# UART3 register map
Vendor: Texas Instruments
Peripheral module from a debugger description file (folder omap36xx).
Registers are 32-bit, access per field, reset 0x0 unless marked. A register's access mark holds for its fields unless they carry their own. Offsets are as the file gives them; lines under a group give offsets from that group; [hi:lo] are bit positions; {n}, {i} and the like mark numbered series; 'fields as' and 'values as' point back to an identical list; <NAME> marks a mode.

## UART3
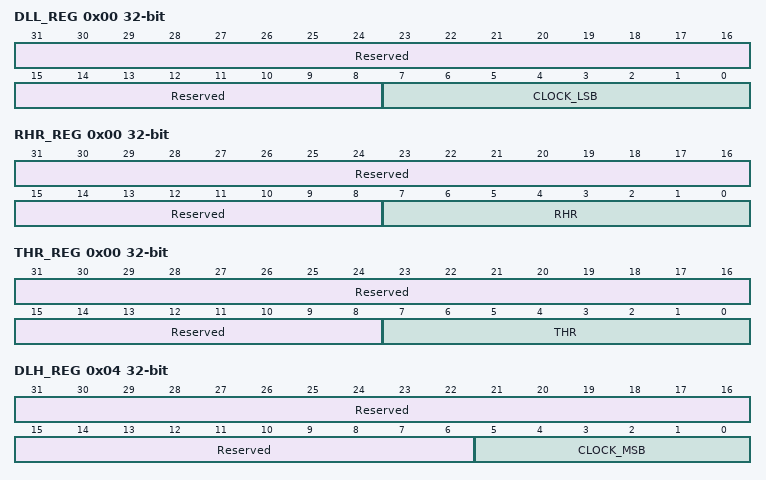
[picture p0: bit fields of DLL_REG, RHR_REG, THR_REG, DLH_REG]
0x00 DLL_REG — Divisor latches low
  [31:8] Reserved ro — Read returns 0.
  [7:0] CLOCK_LSB rw — Stores the 8-bit LSB divisor value
0x00 RHR_REG ro (reset mask 0xFFFFFF00) — Receive holding register
  [31:8] Reserved — Read returns 0.
  [7:0] RHR — Receive holding register
0x00 THR_REG wo (reset mask 0xFFFFFF00) — Transmit holding register
  [31:8] Reserved — Write has no functional effect.
  [7:0] THR — Transmit holding register
0x04 DLH_REG — Divisor latches high
  [31:6] Reserved ro — Read returns 0.
  [5:0] CLOCK_MSB rw — Stores the 6-bit most-significant bit (MSB) divisor value
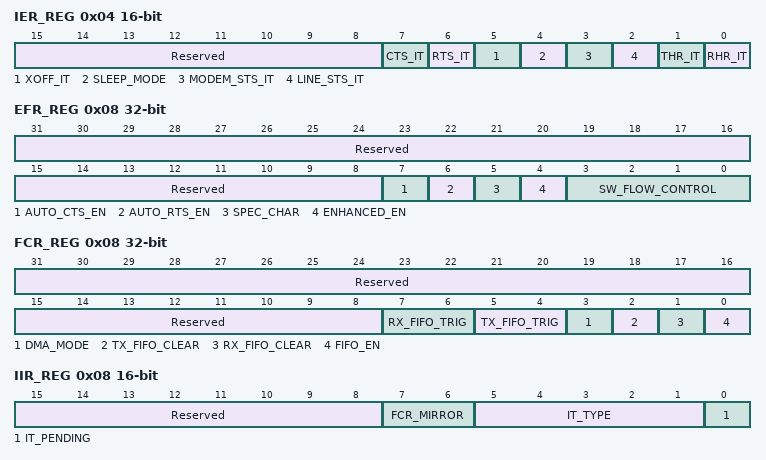
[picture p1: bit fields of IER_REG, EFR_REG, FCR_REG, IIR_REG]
0x04 IER_REG 16-bit rw — Interrupt enable register
  [15:8] Reserved — Read returns 0x00. Write has no functional effect.
  [7] CTS_IT — Can be written only whenEFR_REG[4] = 1
    0=Disables the nCTS interrupt; 1=Enables the nCTS interrupt
  [6] RTS_IT — Can be written only whenEFR_REG[4] = 1
    0=Disables the interrupt; 1=Enables the nRTS interrupt
  [5] XOFF_IT — Can be written only whenEFR_REG[4] = 1
    0=Disables the XOFF interrupt; 1=Enables the XOFF interrupt
  [4] SLEEP_MODE — Can be only written whenEFR_REG[4] = 1
    0=Disables sleep mode; 1=Enables sleep mode (stop baud rate clock when the module is inactive)
  [3] MODEM_STS_IT
    0=Disables the modem status register interrupt; 1=Enables the modem status register interrupt
  [2] LINE_STS_IT
    0=Disables the receiver line status interrupt; 1=Enables the receiver line status interrupt
  [1] THR_IT
    0=Disables the THR interrupt; 1=Enables the THR interrupt
  [0] RHR_IT
    0=Disables the RHR interrupt and time out interrupt; 1=Enables the RHR interrupt and time out interrupt
0x08 EFR_REG — Enhanced feature register
  [31:8] Reserved ro — Read returns 0.
  [7] AUTO_CTS_EN rw — Auto-CTS enable bit (UART mode only)
    0=Normal operation; 1=Auto-CTS flow control is enabled; transmission is halted when the nCTS pin is high (inactive)
  [6] AUTO_RTS_EN rw — Auto-RTS enable bit (UART mode only)
    0=Normal operation; 1=Auto-RTS flow control is enabled; nRTS pin goes high (inactive) when the receiver FIFO HALT trigger level,[3:0], is reached and goes low (active) when the receiver FIFO RESTORE transmission trigger level is reached
  [5] SPEC_CHAR rw — (UART mode only) Special character detect
    0=Normal operation; 1=Special character detect enable. Received data is compared with XOFF2 data. If a match occurs, the received data is transferred to RX FIFO and bit 4 is set to 1 to indicate that a special character was detected.
  [4] ENHANCED_EN rw — Enhanced functions write enable bit
    0=Disables writing to bits [7:4], bits [5:4], and bits [7:5]; 1=Enables writing to bits [7:4], bits [5:4], and bits [7:5]
  [3:0] SW_FLOW_CONTROL rw — Combinations of software flow control can be selected by programming bit [3:0].See. In IrDA mode, bits [1:0] select IR address to check. See , IR Address Checking. .
0x08 FCR_REG wo — FIFO control register
  [31:8] Reserved — Write has no functional effect.
  [7:6] RX_FIFO_TRIG — Sets the trigger level for the RX FIFO: IfSCR_REG[7] = 0 and TLR_REG[7:4]≠ 0000, RX_FIFO_TRIG is not considered.If[7] = 1, RX_FIFO_TRIG is 2 LSB of the trigger level (1 to 63 on 6 bits) with a granularity of 1. . If[7] = 0 and [7:4] = 0000: .
    0=8 characters; 1=16 characters; 2=56 characters; 3=60 characters
  [5:4] TX_FIFO_TRIG — Can be written only ifEFR_REG[4] = 1. Sets the trigger level for the TX FIFO. If SCR_REG[6] = 0 and TLR_REG[3:0] ≠ 0000, TX_FIFO_TRIG is not considered.If[6] = 1, RX_FIFO_TRIG is 2 LSB of the trigger level (1 to 63 on 6 bits) with a granularity of 1. . If[6] = 0 and [3:0] = 0000: .
    0=8 characters; 1=16 characters; 2=32 characters; 3=56 characters
  [3] DMA_MODE — Can be changed only when the baud clock is not running (DLL_REG and DLH_REG set to 0).This register is considered if[0] = 0. .
    0=DMA_MODE 0 (No DMA); 1=DMA_MODE 1 (UART_NDMA_REQ[0] in TX, UART_NDMA_REQ[1] in RX)
  [2] TX_FIFO_CLEAR — Clears the TX FIFO
    0=No change; 1=Clears the transmit FIFO and resets its counter logic to 0. Returns to 0 after clearing FIFO.
  [1] RX_FIFO_CLEAR — Clears the RX FIFO.
    0=No change; 1=Clears the receive FIFO and resets its counter logic to 0. Returns to 0 after clearing FIFO.
  [0] FIFO_EN — Can be changed only when the baud clock is not running (DLL_REG and DLH_REG set to 0).
    0=Disables the transmit and receive FIFOs. The transmit and receive holding registers are 1-byte FIFOs.; 1=Enables the transmit and receive FIFOs. The transmit and receive holding registers are 64-byte FIFOs.
0x08 IIR_REG 16-bit access not given (reset mask 0xFFFE) — Interrupt Identification register
  [15:8] Reserved ro — Read returns 0x00.
  [7:6] FCR_MIRROR ro — Mirror the contents ofFCR_REG[0] on both bits.
  [5:1] IT_TYPE ro — Seven possible interrupts in UART mode; other combinations never occur:
    0=Modem interrupt. Priority = 4; 1=THR interrupt. Priority = 3; 2=RHR interrupt. Priority = 2; 3=Receiver line status error. Priority = 1; 6=Rx timeout. Priority = 2; 8=Xoff/special character. Priority = 5; 16=CTS, RTS change state from active (low) to inactive (high). Priority = 6
  [0] IT_PENDING — 0x0: (access An interrupt is pending.)
    1=No interrupt is pending
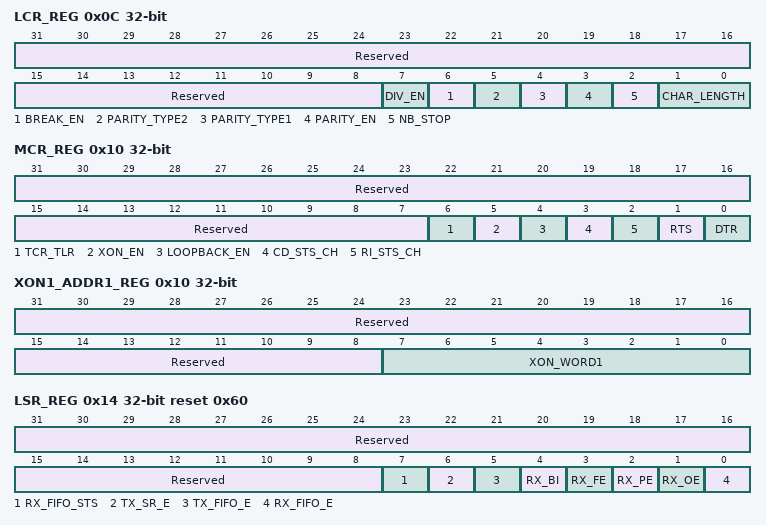
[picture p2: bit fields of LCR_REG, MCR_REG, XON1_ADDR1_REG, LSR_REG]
0x0C LCR_REG — Line control register
  [31:8] Reserved ro — Read returns 0
  [7] DIV_EN rw
    0=Operational mode; 1=Divisor latch enable; put the module in Configuration_Mode_A/B. Allows access to, , and other registers (see , UART/IrDA/CIR Register Mapping Summary). Configuration_Mode_B: [7:0] = 0xBF Else, Configuration_Mode_A
  [6] BREAK_EN rw — Break control bit. UART mode only.Note:When [6] is set to 1, the TX line is forced to 0 and remains in this state as long as [6] = 1. .
    0=Normal operating condition; 1=Forces the transmitter output to go low to alert the communication terminal. TX line is forced to 0 and remains in this state while BREAK_EN = 1.
  [5] PARITY_TYPE2 rw — Selects the forced parity format (ifLCR_REG[3] = 1). UART mode only. If LCR_REG[5] = 1and LCR_REG[4] = 0, the parity bit is forced to 1 in the transmitted and received data. If LCR_REG[5] = 1 and LCR_REG[4] = 1, the parity bit is forced to 0 in the transmitted and received data.
  [4] PARITY_TYPE1 rw — UART mode only
    0=Odd parity is generated (if[3] = 1); 1=Even parity is generated (if[3] = 1)
  [3] PARITY_EN rw — UART mode only
    0=No parity; 1=A parity bit is generated during transmission, and the receiver checks for received parity
  [2] NB_STOP rw — Specifies the number of stop bits. UART mode only.
    0=1 stop bit (word length = 5, 6, 7, 8); 1=1.5 stop bits (word length = 5)1 - 2 stop bits (word length = 6, 7, 8)
  [1:0] CHAR_LENGTH rw — Specifies the word length to be transmitted or received. UART mode only.
    {v}={v+5} bits (v=0..3)
0x10 MCR_REG access not given (reset mask 0xFFFFFFFE) — Modem control register
  [31:7] Reserved ro — Read returns 0.
  [6] TCR_TLR rw — Can be written only whenEFR_REG[4] ENHANCED_EN = 1
    0=No action; 1=Enables access to the and registers
  [5] XON_EN rw — Can be written only whenEFR_REG[4] ENHANCED_EN = 1
    0=Disable XON any function; 1=Enable XON any function
  [4] LOOPBACK_EN rw — In this mode, the[3:0] signals are looped back into [7:4]. The transmit output is looped back to the receive input internally. .
    0=Normal operating mode; 1=Enable local loopback mode (internal)
  [3] CD_STS_CH rw
    0=In loopback, forces nDCD input high and IRQ outputs to INACTIVE state; 1=In loopback, forces nDCD input low and IRQ outputs to INACTIVE state
  [2] RI_STS_CH rw
    0=In loopback, forces nRI input inactive (high); 1=In loopback, forces nRI input active (low)
  [1] RTS rw — In loop back, controlsMSR_REG[4].If auto-RTS is enabled, the nRTS output is controlled by hardware flow control.
    0=Force nRTS output to inactive (high); 1=Force nRTS output to active (low)
  [0] DTR — 0: (access Force DTR output (used in loop back mode) to inactive (high))
    1=Force DTR output (used in loop back mode) to active (low)
0x10 XON1_ADDR1_REG — UART mode: XON1 character, IrDA mode: ADDR1 address
  [31:8] Reserved ro — Read returns 0
  [7:0] XON_WORD1 rw — Used to store the 8-bit XON1 character in UART modes and ADDR1 address 1 for IrDA modes
0x14 LSR_REG ro reset 0x60 — Line status register
  [31:8] Reserved — Read returns 0.
  [7] RX_FIFO_STS
    0=Normal operation; 1=At least one parity error, framing error, or break indication in the RX FIFO. Bit 7 is cleared when no errors are present in the RX FIFO.
  [6] TX_SR_E
    0=Transmitter hold (TX FIFO) and shift registers are not empty; 1=Transmitter hold (TX FIFO) and shift registers are empty
  [5] TX_FIFO_E
    0=Transmit hold register (TX FIFO) is not empty; 1=Transmit hold register (TX FIFO) is empty. The transmission is not necessarily complete.
  [4] RX_BI
    0=No break condition; 1=A break was detected while the data being read from the RX FIFO was being received (RX input was low for one character + 1 bit time frame)
  [3] RX_FE
    0=No framing error in data being read from RX FIFO; 1=Framing error occurred in data being read from RX FIFO (received data did not have a valid stop bit)
  [2] RX_PE
    0=No parity error in data being read from RX FIFO; 1=Parity error in data being read from RX FIFO
  [1] RX_OE
    0=No overrun error; 1=Overrun error occurred. Set when the character held in the receive shift register is not transferred to the RX FIFO. This case occurs only when receive FIFO is full.
  [0] RX_FIFO_E
    0=No data in the receive FIFO; 1=At least one data character in the RX FIFO
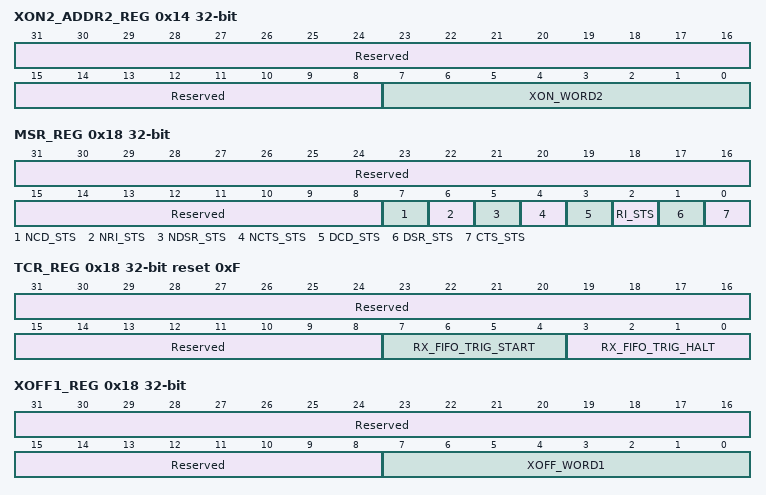
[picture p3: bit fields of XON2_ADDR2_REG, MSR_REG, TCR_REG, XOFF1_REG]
0x14 XON2_ADDR2_REG
  [31:8] Reserved ro — Read returns 0.
  [7:0] XON_WORD2 rw — Stores the 8-bit XON2 character in UART modes and ADDR2 address 2 for IrDA modes
0x18 MSR_REG ro (reset mask 0xFFFFFF0F) — Modem status register. UART mode only.
  [31:8] Reserved — Read returns 0x00.
  [7] NCD_STS — In loopback mode, it is equivalent toMCR_REG[3].
  [6] NRI_STS — This bit is the complement of the nRI input. In loopback mode, it is equivalent toMCR_REG[2].
  [5] NDSR_STS — In loopback mode, it is equivalent toMCR_REG[0].
  [4] NCTS_STS — This bit is the complement of the nCTS input. In loopback mode, it is equivalent toMCR_REG[1].
  [3] DCD_STS — Indicates thatMCR_REG[3] in loopback changed. Cleared on a read.
  [2] RI_STS — Indicates that nRI input (orMCR_REG[2] in loopback) changed state from low to high. Cleared on a read.
  [1] DSR_STS
    1=Indicates that[0] in loopback changed state. Cleared on a read.
  [0] CTS_STS
    1=Indicates that nCTS input (or[1] in loopback) changed state. Cleared on a read.
0x18 TCR_REG reset 0xF — Transmission control register.
  [31:8] Reserved ro — Read returns 0.
  [7:4] RX_FIFO_TRIG_START rw — RX FIFO trigger level to RESTORE transmission (0 to 60)
  [3:0] RX_FIFO_TRIG_HALT rw — RX FIFO trigger level to HALT transmission (0 to 60)
0x18 XOFF1_REG — UART mode XOFF1 character
  [31:8] Reserved ro — Read returns 0
  [7:0] XOFF_WORD1 rw — Stores the 8-bit XOFF1 character used in UART modes
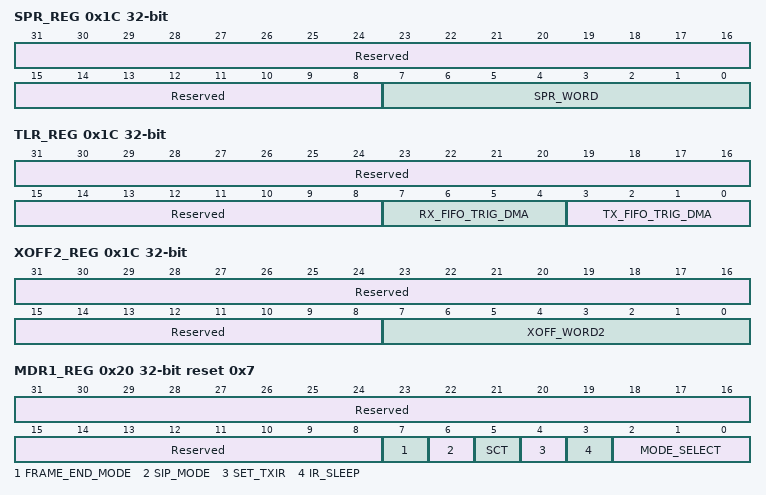
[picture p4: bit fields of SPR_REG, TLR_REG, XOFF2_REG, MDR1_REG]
0x1C SPR_REG — Scratchpad register
  [31:8] Reserved ro — Read returns 0x00.
  [7:0] SPR_WORD rw — Scratchpad register
0x1C TLR_REG — Trigger level register.
  [31:8] Reserved ro — Read returns 0x00.
  [7:4] RX_FIFO_TRIG_DMA rw — Receive FIFO trigger level
  [3:0] TX_FIFO_TRIG_DMA rw — Transmit FIFO trigger level
0x1C XOFF2_REG — UART mode XOFF2 character.
  [31:8] Reserved ro — Read returns 0.
  [7:0] XOFF_WORD2 rw — Stores the 8-bit XOFF2 character used in UART modes
0x20 MDR1_REG reset 0x7 — Mode definition register 1.
  [31:8] Reserved ro — Read returns 0.
  [7] FRAME_END_MODE rw — IrDA mode only
    0=Frame-length method; 1=Set EOT bit method
  [6] SIP_MODE rw — MIR/FIR modes only. IrDA only.
    0=Manual SIP mode: SIP is generated with the control of[3]; 1=Automatic SIP mode: SIP is generated after each transmission
  [5] SCT rw — Store and control the transmission.Note:Before starting any transmission, there must be no reception ongoing. .
    0=Starts the infrared transmission when a value is written to; 1=Starts the infrared transmission with the control of[2]
  [4] SET_TXIR rw — Used to configure the infrared transceiver. IrDA only.
    0=a) No action if MDR2[7]=0b) TXIR pin output is forced low if MDR2[7]=1; 1=TXIR pin output is forced high (not dependant on value of MDR2[7])
  [3] IR_SLEEP rw
    0=IrDA/CIR sleep mode disabled; 1=IrDA/CIR sleep mode enabled
  [2:0] MODE_SELECT rw — UART-IrDA-CIR mode selection
    0=UART 16x mode; 1=SIR mode; 2=UART 16x auto-baud; 3=UART 13x mode; 4=MIR mode; 5=FIR mode; 6=CIR mode; 7=Disable (default state)
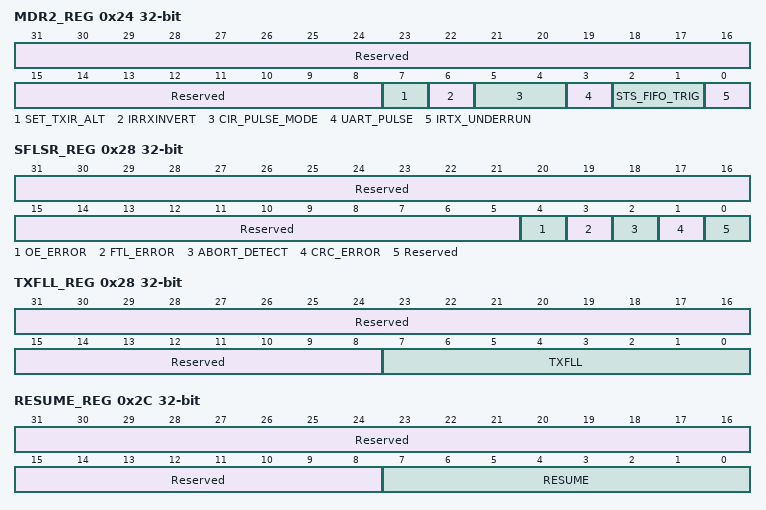
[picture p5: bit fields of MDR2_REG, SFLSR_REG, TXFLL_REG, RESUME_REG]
0x24 MDR2_REG — Mode definition register 2
  [31:8] Reserved ro — Read returns 0x00.
  [7] SET_TXIR_ALT rw — Provide alternate functionnality for MDR1[4] (SET_TXIR)
    0=Normal mode; 1=Alternate mode for SET_TXIR
  [6] IRRXINVERT rw — Only for IR mode (IrDA and CIR). Invert RX pin in the module before the voting or sampling system logic of the infrared block. This does not affect the RX path in UART modem modes.
    0=Inversion is performed; 1=No inversion is performed
  [5:4] CIR_PULSE_MODE rw — CIR pulse modulation definition. Defines high level of the pulse width associated with a digit:
    {v}=Pulse width of {v+3} from 12 cycles (v=0..3)
  [3] UART_PULSE rw — UART mode only. Used to allow pulse shaping in UART mode.
    0=Normal UART mode; 1=UART mode with pulse shaping
  [2:1] STS_FIFO_TRIG rw — Only for IR-IrDA modeFrame status FIFO threshold select: .
    0=1 entry; 1=4 entries; 2=7 entries; 3=8 entries
  [0] IRTX_UNDERRUN ro — IrDA transmission status interrupt. When theIIR_REG[5] interrupt occurs, the meaning of the interrupt is:
    0=The last bit of the frame was transmitted successfully without error; 1=An underrun occurred. The last bit of the frame was transmitted but with an underrun error. The bit is reset to 0 when the register is read.
0x28 SFLSR_REG ro (reset mask 0xFFFFFFE1) — Status FIFO line status register
  [31:5] Reserved — Read returns 0.
  [4] OE_ERROR
    1=Overrun error in RX FIFO when frame at top of RX FIFO was received. Top of RX FIFO = next frame to be read from RX FIFO.
  [3] FTL_ERROR — Frame-too-long error
    1=Frame-length too long error in frame at top of RX FIFO
  [2] ABORT_DETECT
    1=Abort pattern detected in frame at top of RX FIFO; 1=CRC error in frame at top of RX FIFO
  [1] CRC_ERROR
  [0] Reserved — Read returns 0.
0x28 TXFLL_REG wo — Transmit frame length register low
  [31:8] Reserved — Write has no functional effect.
  [7:0] TXFLL — LSB register used to specify the frame length
0x2C RESUME_REG ro — IR-IrDA and IR-CIR modes only
  [31:8] Reserved — Read returns 0x00
  [7:0] RESUME — Dummy read to restart the TX or RX
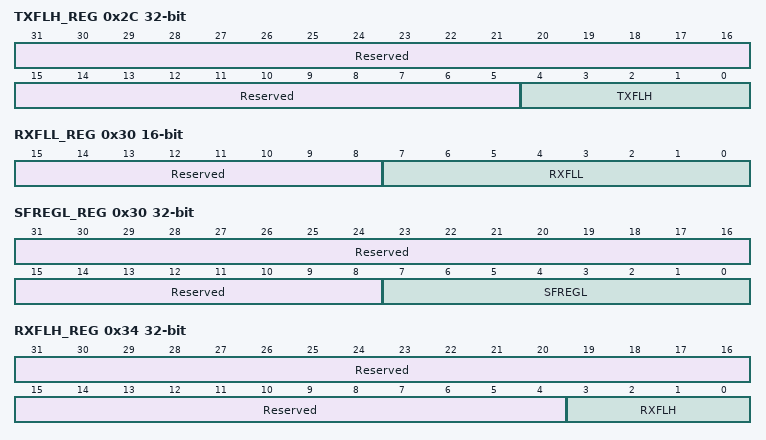
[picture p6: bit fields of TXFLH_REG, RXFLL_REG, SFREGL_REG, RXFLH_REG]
0x2C TXFLH_REG — Transmit frame length register low
  [31:5] Reserved ro — Read returns 0.
  [4:0] TXFLH wo — MSB register used to specify the frame length
0x30 RXFLL_REG 16-bit wo — Received frame length register low
  [15:8] Reserved — Write has no functional effect.
  [7:0] RXFLL — LSB register used to specify the frame length in reception
0x30 SFREGL_REG ro (reset mask 0xFFFFFF00) — Status FIFO register low
  [31:8] Reserved — Read returns 0x00.
  [7:0] SFREGL — LSB part of the frame length
0x34 RXFLH_REG wo — Received frame length register high
  [31:4] Reserved — Write has no functional effect.
  [3:0] RXFLH — MSB register used to specify the frame length in reception
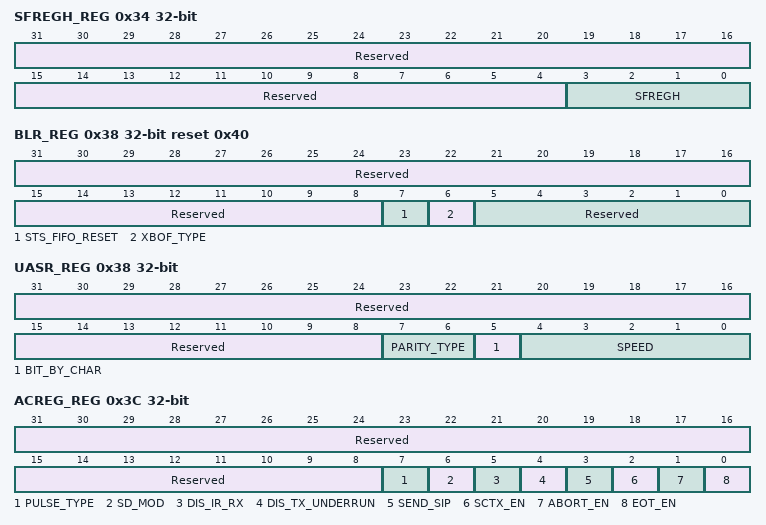
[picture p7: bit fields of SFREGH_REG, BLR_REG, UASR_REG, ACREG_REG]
0x34 SFREGH_REG ro (reset mask 0xFFFFFFF0) — Status FIFO register high
  [31:4] Reserved — Read returns 0.
  [3:0] SFREGH — MSB part of the frame length
0x38 BLR_REG reset 0x40 — BOF control register
  [31:8] Reserved ro — Read returns 0.
  [7] STS_FIFO_RESET rw — Status FIFO reset. This bit is self-clearing.
  [6] XBOF_TYPE rw — SIR xBOF select
    0=0xFF; 1=0xC0
  [5:0] Reserved ro — Read returns 0x00.
0x38 UASR_REG ro — UART autobauding status register
  [31:8] Reserved — Read returns 0.
  [7:6] PARITY_TYPE
    0=No parity identified; 1=Parity space; 2=Even parity; 3=Odd parity
  [5] BIT_BY_CHAR
    0=7-bit character identified; 1=8-bit character identified
  [4:0] SPEED — Used to report the speed identified
    0=No speed identified; 1=115 200 baud; 2=57 600 baud; 3=38 400 baud; 4=28 800 baud; 5=19 200 baud; 6=14 400 baud; 7=9 600 baud; 8=4 800 baud; 9=4 800 baud; 10=1 200 baud
0x3C ACREG_REG — Auxiliary control register
  [31:8] Reserved ro — Read returns 0.
  [7] PULSE_TYPE rw — SIR pulse-width select:
    0=3/16 of baud-rate pulse width; 1=1.6 µs
  [6] SD_MOD rw — Primary output used to configure transceivers. Connected to the SD/MODE input pin of IrDA transceivers.
    0=SD pin is set to high; 1=SD pin is set to low
  [5] DIS_IR_RX rw
    0=Normal operation (RX input automatically disabled during transmit, but enabled outside of transmit operation); 1=Disables RX input (permanent state; independent of transmit)
  [4] DIS_TX_UNDERRUN rw
    0=Long stop bits cannot be transmitted. TX underrun is enabled.; 1=Long stop bits can be transmitted. TX underrun is disabled.
  [3] SEND_SIP rw — MIR/FIR modes only. Send serial infrared interaction pulse (SIP).If this bit is set during an MIR/FIR transmission, the SIP is sent at the end of it. This bit is automatically cleared at the end of the SIP transmission. .
    0=No action; 1=Send SIP pulse
  [2] SCTX_EN rw — Store and control TX start. WhenMDR1_REG[5] = 1 and the MPU writes 1 to this bit, the TX state-machine starts frame transmission. This bit is self-clearing.
  [1] ABORT_EN rw — Frame abort. The MPU can intentionally abort transmission of a frame by writing 1 to this bit. Neither the end flag nor the CRC bits are appended to the frame.
  [0] EOT_EN rw — EOT (end-of-transmission) bit. The MPU writes 1 to this bit just before it writes the last byte to the TX FIFO in the set-EOT bit frame-closing method. This bit is automatically cleared when the MPU writes to theTHR_REG (TX FIFO).
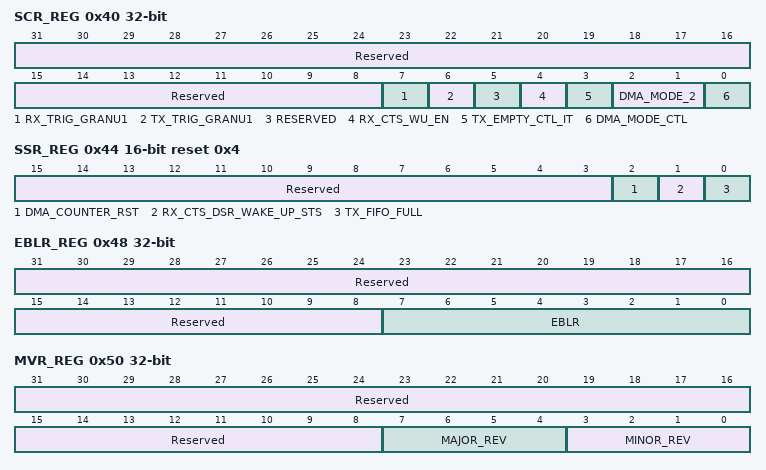
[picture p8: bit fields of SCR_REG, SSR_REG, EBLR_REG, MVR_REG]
0x40 SCR_REG — Supplementary control register
  [31:8] Reserved ro — Read returns 0.
  [7] RX_TRIG_GRANU1 rw
    0=Disables the granularity of 1 for TRIGGER RX level; 1=Enables the granularity of 1 for TRIGGER RX level
  [6] TX_TRIG_GRANU1 rw
    0=Disables the granularity of 1 for TRIGGER TX level; 1=Enables the granularity of 1 for trigger TX level
  [5] RESERVED ro — Read returns 0. Write has no functional effect.
  [4] RX_CTS_WU_EN rw — RX CTS wake-up enable
    0=Disables the WAKE UP interrupt and clears[1]; 1=Waits for a falling edge of pins RX, nCTS, or nDSR to generate an interrupt
  [3] TX_EMPTY_CTL_IT rw
    0=Normal mode for THR interrupt (see for details about UART mode interrupts); 1=The THR interrupt is generated when TX FIFO and TX shift register are empty
  [2:1] DMA_MODE_2 rw — Specifies the DMA mode valid ifSCR_REG[0] = 1
    0=DMA mode 0 (no DMA); 1=DMA mode 1 (UARTi_DMA_TX, UARTi_DMA_RX); 2=DMA mode 2 (UARTi_DMA_RX); 3=DMA mode 3 (UARTi_DMA_TX)
  [0] DMA_MODE_CTL rw
    0=The DMA_MODE is set with[3]; 1=The DMA_MODE is set with[2:1]
0x44 SSR_REG 16-bit reset 0x4 — Supplementary status register
  [15:3] Reserved ro — Read returns 0.
  [2] DMA_COUNTER_RST rw — DMA counter reset.
    0=The DMA counter will not be reset if the corresponding FIFO is reset (via FCR[1] or FCR[2]); 1=The DMA counter will be reset if corresponding FIFO is reset (via FCR[1] or FCR[2])
  [1] RX_CTS_DSR_WAKE_UP_STS ro — Pin falling edge detection: Reset only whenSCR_REG[4] is reset to 0.
    0=No falling-edge event on RX, nCTS, and nDSR; 1=A falling edge occurred on RX, nCTS, or nDSR
  [0] TX_FIFO_FULL ro — TX FIFO status.
    0=TX FIFO is not full; 1=TX FIFO is full
0x48 EBLR_REG — BOF length register.
  [31:8] Reserved ro — Read returns 0.
  [7:0] EBLR rw — IR-IrDA mode: This register allows definition of up to 176 xBOFs, the maximum required by IrDA specification.IR-CIR mode: N/A
    0=Feature disabled; 1=Generate RX_STOP interrupt after receiving one zero bit; 255=Generate RX_STOP interrupt after receiving 255 zero bits
0x50 MVR_REG ro (reset mask 0xFFFFFF00) — Module version register
  [31:8] Reserved — Read returns 0.
  [7:4] MAJOR_REV — Major revision of the module
  [3:0] MINOR_REV — Minor revision of the module
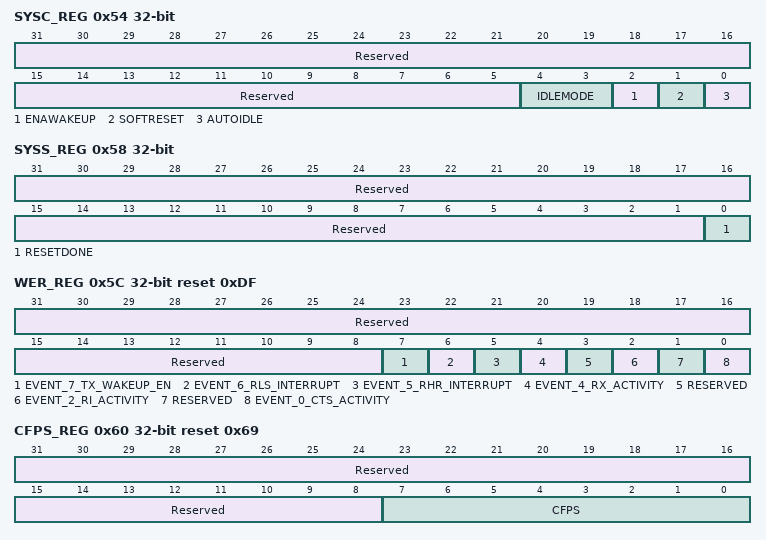
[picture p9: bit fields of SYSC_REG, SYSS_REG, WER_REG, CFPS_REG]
0x54 SYSC_REG — System configuration register.
  [31:5] Reserved ro — Read returns 0.
  [4:3] IDLEMODE rw — Power management req/ack control
    0=Force idle: Idle request is acknowledged unconditionally; 1=No-idle: Idle request is never acknowledged; 2=Smart idle: Idle request is acknowledged based on the internal module activity
  [2] ENAWAKEUP rw — Wakeup control
    0=Wakeup is disabled; 1=Wakeup capability is enabled
  [1] SOFTRESET rw — Software reset. Set this bit to 1 to trigger a module reset. This bit is automatically reset by the hardware. Read returns 0.
    0=Normal mode; 1=The module is reset
  [0] AUTOIDLE rw — Internal interface clock-gating strategy
    0=Clock is running; 1=Automatic interface clock-gating strategy is applied based on interface activity
0x58 SYSS_REG ro — System status register
  [31:1] Reserved — Read returns 0.
  [0] RESETDONE — Internal reset monitoring
    0=Internal module reset is ongoing; 1=Reset complete
0x5C WER_REG access not given reset 0xDF (reset mask 0xFFFFFFDF) — Wake-up enable register
  [31:8] Reserved ro — Read returns 0x00.
  [7] EVENT_7_TX_WAKEUP_EN rw — Receiver line status interrupt
    0=Event is not allowed to wake up the system; 1=EVENT CAN WAKE UP THE SYSTEM: Event can be: THR_IT or TX_DMA request and/or TX_SATUS_IT
  [6] EVENT_6_RLS_INTERRUPT rw — Receiver line status interrupt
    0=Event is not allowed to wake up the system; 1=Event can wake up the system
  [5] EVENT_5_RHR_INTERRUPT
    values as EVENT_6_RLS_INTERRUPT
  [4] EVENT_4_RX_ACTIVITY rw
    values as EVENT_6_RLS_INTERRUPT
  [3] RESERVED rw — Read returns 1. Must be set to 1 for correct behavior.
  [2] EVENT_2_RI_ACTIVITY rw
    values as EVENT_6_RLS_INTERRUPT
  [1] RESERVED rw — Read returns 1. Must be set to 1 for correct behavior.
  [0] EVENT_0_CTS_ACTIVITY rw — UART mode only
    values as EVENT_6_RLS_INTERRUPT
0x60 CFPS_REG reset 0x69 — Carrier frequency prescaler
  [31:8] Reserved ro — Read returns 0.
  [7:0] CFPS rw — Because the consumer IR works at modulation rates of 30-56.8 kHz, the 48-MHz clock must be prescaled before the clock can drive the IR logic. This register sets the divisor rate to give a range to accommodate remote-control requirements in BAUD multiples of 12x. The value of the CFPS at reset is 0105 (decimal), which equates to a 38.1-kHz output from starting conditions. The 48-MHz carrier is prescaled by the CFPS, which is then divided by the 12x BAUD multiple.Example: . Target Freq (kHz) CFPS (decimal) Actual Freq(kHz) . 30 133 30.08 . 32.75 122 32.79 . 36 111 36.04 . 36.7 109 36.69 . 38 105 38.1 . 40 100 40 . 56.8 70 57.14 . CFPS = 0 is not supported. .
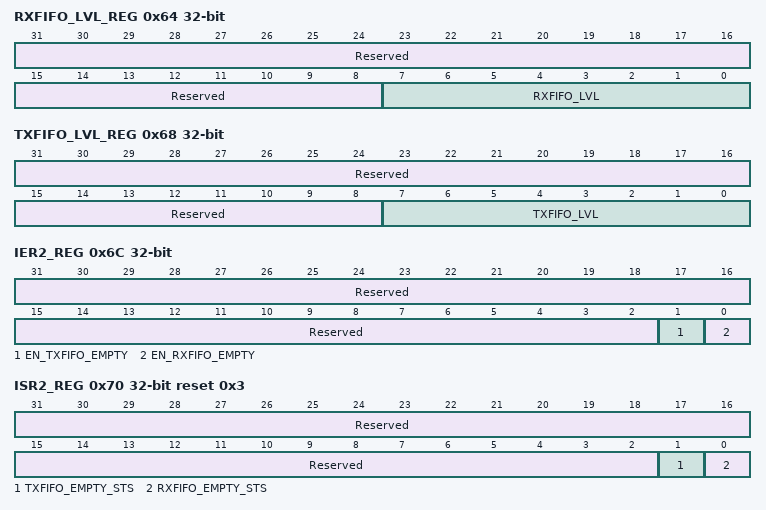
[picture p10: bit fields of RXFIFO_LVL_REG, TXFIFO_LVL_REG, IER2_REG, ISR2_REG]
0x64 RXFIFO_LVL_REG ro — Level of the RX FIFO
  [31:8] Reserved — Read returns 0.
  [7:0] RXFIFO_LVL — Shows the number of received bytes in the RX FIFO.
0x68 TXFIFO_LVL_REG ro — Level of the TX FIFO
  [31:8] Reserved — Read returns 0x00.
  [7:0] TXFIFO_LVL — Shows the number of received bytes in the TX FIFO.
0x6C IER2_REG — Enables RX/TX FIFOs empty corresponding interrupts.
  [31:2] Reserved ro — Read returns 0.
  [1] EN_TXFIFO_EMPTY rw — Enables TX FIFO empty corresponding interrupt
    0=Enables EN_TXFIFO_EMPTY interrupt; 1=Disables EN_TXFIFO_EMPTY interrupt
  [0] EN_RXFIFO_EMPTY rw — Enables RX FIFO empty corresponding interrupt
    0=Enables EN_RXFIFO_EMPTY interrupt; 1=Disables EN_RXFIFO_EMPTY interrupt
0x70 ISR2_REG reset 0x3 — Status of RX/TX FIFOs empty corresponding interrupts.
  [31:2] Reserved ro — Read returns 0.
  [1] TXFIFO_EMPTY_STS rw — Used to generate interrupt if the TX_FIFO is empty (software flow control)
    0=TXFIFO_EMPTY interrupt not pending; 1=TXFIFO_EMPTY interrupt pending
  [0] RXFIFO_EMPTY_STS rw — Used to generate interrupt if the RX_FIFO is empty (software flow control)
    0=RXFIFO_EMPTY interrupt not pending; 1=RXFIFO_EMPTY interrupt pending
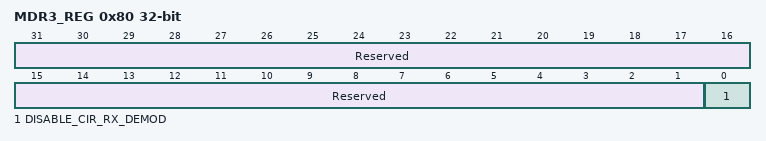
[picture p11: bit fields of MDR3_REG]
0x80 MDR3_REG — Mode definition register 3.
  [31:1] Reserved ro — Read returns 0.
  [0] DISABLE_CIR_RX_DEMOD rw — Used to enable CIR RX demodulation.
    0=Enables CIR RX demodulation; 1=Disables CIR RX demodulation
